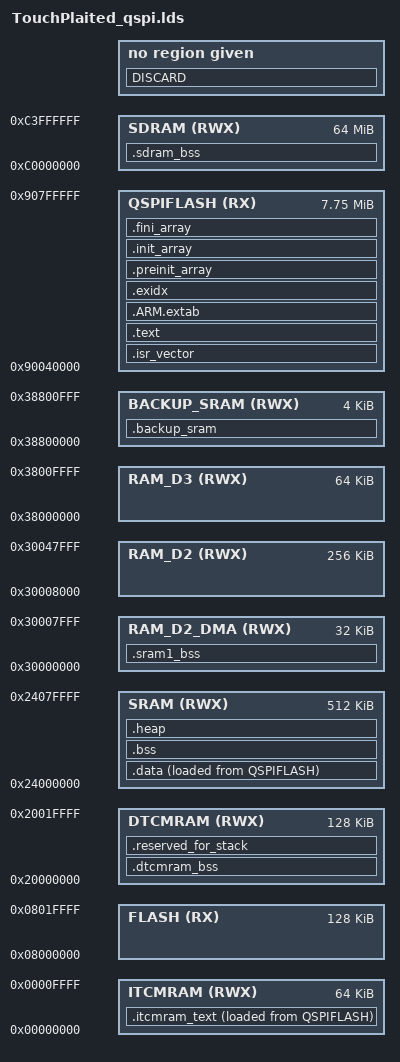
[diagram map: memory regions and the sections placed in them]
/* Generated by LinkerScriptGenerator [http://visualgdb.com/tools/LinkerScriptGenerator]
 * Target: STM32H750IB
 * The file is provided under the BSD license.
 * yeah okay but i also modified it a lot so like, give me some credit too mr BSD
 */

/* ---------------------------------------------------------------------------
 * TouchPlaited copy of libDaisy's core/STM32H750IB_qspi.lds.
 *
 * Selected via LDSCRIPT in the project Makefile (core/Makefile declares it
 * with ?=, so setting it before the include wins). Kept here rather than in
 * the libDaisy fork because the one change below is specific to this
 * firmware's data, not something upstream would want.
 *
 * The change: the Six-Op render path executes from ITCM instead of QSPI.
 * Everything runs from external QSPI flash on this part, so every instruction
 * the audio ISR fetches is a serial-flash access through a 16KB I-cache.
 * ITCMRAM is 64KB of zero-wait-state memory on its own bus, and it was 100%
 * unused.
 *
 * This is the *second* thing tried here. The first moved Plaits' lookup
 * tables (resources.o, ~75KB of .rodata) into DTCM on the same reasoning
 * applied to data, and it was measured on 2026-08-10 at ~1% flat with the
 * per-voice slope completely unchanged — see notes.md, "Plaits' tables in
 * DTCM". That result is what justifies this one: data fetch was ruled out by
 * measurement, so instruction fetch is what is left. DTCM is back to
 * untouched here, and the stack has its full 128KB again.
 *
 * Two mechanics make it work:
 *   - .text below excludes the hot objects via EXCLUDE_FILE, so their code
 *     falls through to .itcmram_text further down. Everything else's .text
 *     and all .rodata keep their position, so the flash image layout is
 *     otherwise untouched.
 *   - .itcmram_text runs in ITCMRAM but loads from QSPIFLASH (same AT >
 *     pattern as .data), and a priority-101 constructor copies it before
 *     anything calls into it. Nothing may call these functions before that
 *     copy — see copy_itcm_text() in TouchPlaited.cpp.
 *
 * ITCM is at 0x00000000 and QSPI at 0x90040000, far outside the ±16MB range
 * of a Thumb bl, so every call across the boundary goes through a long-branch
 * veneer that ld inserts automatically. That is a real per-call cost and part
 * of what is being measured: it is why whole call-graphs move together rather
 * than individual hot functions.
 * ------------------------------------------------------------------------ */

ENTRY(Reset_Handler)

MEMORY
{
	FLASH       (RX)  : ORIGIN = 0x08000000, LENGTH = 128K
	DTCMRAM     (RWX) : ORIGIN = 0x20000000, LENGTH = 128K
	SRAM        (RWX) : ORIGIN = 0x24000000, LENGTH = 512K
	RAM_D2_DMA  (RWX) : ORIGIN = 0x30000000, LENGTH = 32K
	RAM_D2      (RWX) : ORIGIN = 0x30008000, LENGTH = 256K
	RAM_D3      (RWX) : ORIGIN = 0x38000000, LENGTH = 64K
	BACKUP_SRAM (RWX) : ORIGIN = 0x38800000, LENGTH = 4K
	ITCMRAM     (RWX) : ORIGIN = 0x00000000, LENGTH = 64K
	SDRAM       (RWX) : ORIGIN = 0xc0000000, LENGTH = 64M
	QSPIFLASH   (RX)  : ORIGIN = 0x90040000, LENGTH = 7936K
}

_estack = 0x20020000;

SECTIONS
{
	.isr_vector :
	{
		. = ALIGN(4);
		KEEP(*(.isr_vector))
		. = ALIGN(4);
	} > QSPIFLASH

	.text :
	{
		. = ALIGN(4);
		_stext = .;

		/* The Six-Op render path is claimed by .itcmram_text below.
		   Everything else's code stays here in QSPI as before. Keep this
		   list identical to the one in .itcmram_text — a name that appears
		   in one and not the other either duplicates the code or leaves it
		   in QSPI, both silently.

		   Exact build/ paths rather than *-globs, deliberately: `*voice.o`
		   also matches string_voice.o and modal_voice.o, which quietly
		   relocated two unrelated engines the first time this was built,
		   and would silently capture any future *_voice.cc as well. The
		   cost of being exact is that these patterns depend on make passing
		   relative paths to ld — which the size ASSERT at the end of this
		   file exists to catch. */
		*(EXCLUDE_FILE(build/six_op_engine.o build/algorithms.o build/voice.o build/plaits_voice.o) .text)
		*(EXCLUDE_FILE(build/six_op_engine.o build/algorithms.o build/voice.o build/plaits_voice.o) .text*)
		/* .rodata all stays in QSPI: moving it to DTCM was measured at ~1%
		   and reverted. See the header comment. */
		*(.rodata)
		*(.rodata*)
		*(.glue_7)
		*(.glue_7t)
		KEEP(*(.init))
		KEEP(*(.fini))
		. = ALIGN(4);
		_etext = .;

	} > QSPIFLASH

	.ARM.extab :
	{
		. = ALIGN(4);
		*(.ARM.extab)
		*(.gnu.linkonce.armextab.*)
		. = ALIGN(4);
	} > QSPIFLASH

	.exidx :
	{
		. = ALIGN(4);
		PROVIDE(__exidx_start = .);
		*(.ARM.exidx*)
		. = ALIGN(4);
		PROVIDE(__exidx_end = .);
	} > QSPIFLASH

	.ARM.attributes 0 : { *(.ARM.attributes) }

	.preinit_array :
	{
		PROVIDE_HIDDEN(__preinit_array_start = .);
		KEEP(*(.preinit_array*))
		PROVIDE_HIDDEN(__preinit_array_end = .);
	} > QSPIFLASH

	.init_array :
	{
		PROVIDE_HIDDEN(__init_array_start = .);
		KEEP(*(SORT(.init_array.*)))
		KEEP(*(.init_array*))
		PROVIDE_HIDDEN(__init_array_end = .);
	} > QSPIFLASH

	.fini_array :
	{
		PROVIDE_HIDDEN(__fini_array_start = .);
		KEEP(*(.fini_array*))
		KEEP(*(SORT(.fini_array.*)))
		PROVIDE_HIDDEN(__fini_array_end = .);
	} > QSPIFLASH

	.sram1_bss (NOLOAD) :
	{
		. = ALIGN(4);
		_ssram1_bss = .;

		PROVIDE(__sram1_bss_start__ = _sram1_bss);
		*(.sram1_bss)
		*(.sram1_bss*)
		. = ALIGN(4);
		_esram1_bss = .;

		PROVIDE(__sram1_bss_end__ = _esram1_bss);
	} > RAM_D2_DMA

	.data :
	{
		. = ALIGN(4);
		_sdata = .;

		PROVIDE(__data_start__ = _sdata);
		*(.data)
		*(.data*)
		. = ALIGN(4);
		_edata = .;

		PROVIDE(__data_end__ = _edata);
	} > SRAM AT > QSPIFLASH

	_sidata = LOADADDR(.data);

	.bss (NOLOAD) :
	{
		. = ALIGN(4);
		_sbss = .;

		PROVIDE(__bss_start__ = _sbss);
		*(.bss)
		*(.bss*)
		*(COMMON)
		. = ALIGN(4);
		_ebss = .;

		PROVIDE(__bss_end__ = _ebss);
	} > SRAM

	/* Runs in ITCM, loads from QSPI — copy_itcm_text() in TouchPlaited.cpp
	   does the copy, as a constructor(101) so it lands ahead of every static
	   ctor. ITCM is otherwise entirely ours: nothing else in this script or
	   in libDaisy places anything there. Keep this list identical to the
	   EXCLUDE_FILE list up in .text. */
	.itcmram_text :
	{
		. = ALIGN(4);
		_sitcmram_text = .;

		build/six_op_engine.o(.text .text*)
		build/algorithms.o(.text .text*)
		build/voice.o(.text .text*)
		build/plaits_voice.o(.text .text*)
		. = ALIGN(4);
		_eitcmram_text = .;

	} > ITCMRAM AT > QSPIFLASH

	_sitcmram_text_load = LOADADDR(.itcmram_text);

	.dtcmram_bss (NOLOAD) :
	{
		. = ALIGN(4);
		_sdtcmram_bss = .;

		PROVIDE(__dtcmram_bss_start__ = _sdtcmram_bss);
		*(.dtcmram_bss)
		*(.dtcmram_bss*)
		. = ALIGN(4);
		_edtcmram_bss = .;

		PROVIDE(__dtcmram_bss_end__ = _edtcmram_bss);
	} > DTCMRAM

	/*
	.sdram_text :
	{
		. = ALIGN(4);
		_ssdram_text = .;

		PROVIDE(__sdram_text_start = _ssdram_text);
		*(.sdram_text)
		*(.sdram_text*)
		. = ALIGN(4);
		_esdram_text = .;

		PROVIDE(__sdram_text_end = _esdram_text);
	} > SDRAM AT >FLASH
	_sisdram_text = LOADADDR(.sdram_text);
	*/

	.sdram_bss (NOLOAD) :
	{
		. = ALIGN(4);
		_ssdram_bss = .;

		PROVIDE(__sdram_bss_start = _ssdram_bss);
		*(.sdram_bss)
		*(.sdram_bss*)
		. = ALIGN(4);
		_esdram_bss = .;

		PROVIDE(__sdram_bss_end = _esdram_bss);
	} > SDRAM

	.backup_sram (NOLOAD) :
	{
		. = ALIGN(4);
		_sbackup_sram = .;

		PROVIDE(__backup_sram_start = _sbackup_sram);
		*(.backup_sram)
		*(.backup_sram*)
		. = ALIGN(4);
		_ebackup_sram = .;

		PROVIDE(__backup_sram_end = _ebackup_sram);
	} > BACKUP_SRAM


    /* .qspiflash_text :
	{
		. = ALIGN(4);
		_sqspiflash_text = .;

		PROVIDE(__qspiflash_text_start = _sqspiflash_text);
		*(.qspiflash_text)
		*(.qspiflash_text*)
		. = ALIGN(4);
		_eqspiflash_text = .;

		PROVIDE(__qspiflash_text_end = _eqspiflash_text);
	} > QSPIFLASH

	.qspiflash_data :
	{
		. = ALIGN(4);
		_sqspiflash_data = .;

		PROVIDE(__qspiflash_data_start = _sqspiflash_data);
		*(.qspiflash_data)
		*(.qspiflash_data*)
		. = ALIGN(4);
		_eqspiflash_data = .;

		PROVIDE(__qspiflash_data_end = _eqspiflash_data);
	} > QSPIFLASH

	.qspiflash_bss (NOLOAD) :
	{
		. = ALIGN(4);
		_sqspiflash_bss = .;

		PROVIDE(__qspiflash_bss_start = _sqspiflash_bss);
		*(.qspiflash_bss)
		*(.qspiflash_bss*)
		. = ALIGN(4);
		_eqspiflash_bss = .;

		PROVIDE(__qspiflash_bss_end = _eqspiflash_bss);
	} > QSPIFLASH */

	.heap (NOLOAD) :
	{
		. = ALIGN(4);
		PROVIDE(__heap_start__ = .);
		PROVIDE(__heap_start = .);
		KEEP(*(.heap))
		. = ALIGN(4);
		PROVIDE(__heap_end = .);
		PROVIDE(__heap_end__ = .);
	} > SRAM

	PROVIDE(end = .);

	.reserved_for_stack (NOLOAD) :
	{
		. = ALIGN(4);
		PROVIDE(__reserved_for_stack_start__ = .);
		KEEP(*(.reserved_for_stack))
		. = ALIGN(4);
		PROVIDE(__reserved_for_stack_end__ = .);
	} > DTCMRAM

    DISCARD :
    {
        libc.a ( * )
        libm.a ( * )
        libgcc.a ( * )
    }

	/* The object-name patterns above are globs against whatever paths make
	   happened to pass to ld. If one stops matching — a file renamed, a
	   source moved between directories, a build invoked from somewhere
	   unexpected — the code silently stays in QSPI and the experiment
	   quietly measures nothing. That is the same shape of failure as the
	   stale libdaisy.a (notes.md): everything builds, everything runs, the
	   number is just wrong. Fail the link instead.

	   A bare non-empty check is not enough: the four patterns are
	   independent, so three could match and one silently miss, leaving the
	   hottest function in QSPI while the build looks fine. The four objects
	   measured 20360 bytes together on 2026-08-10; 16K is a floor loose
	   enough to survive ordinary code churn and tight enough that losing
	   any one of them trips it. If this fires after a deliberate change to
	   the list, update the number — do not delete the check. */
	ASSERT(_eitcmram_text - _sitcmram_text >= 16K,
	       "ITCM text is under 16K - an object pattern probably stopped matching")
}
